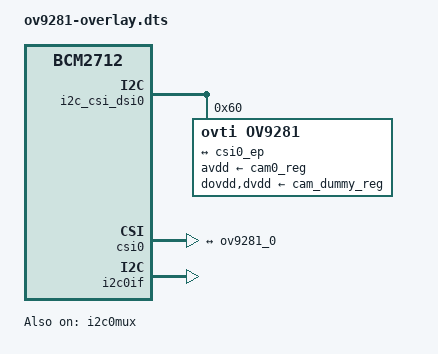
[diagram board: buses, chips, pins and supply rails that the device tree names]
/*
 * OV9281 Global Shutter Camera Device Tree Overlay
 * Raspberry Pi 5 - MIPI CSI-2 - 1MP Global Shutter
 */

/dts-v1/;
/plugin/;

/ {
    compatible = "brcm,bcm2712";
    
    fragment@0 {
        target = <&i2c_csi_dsi0>;
        __overlay__ {
            #address-cells = <1>;
            #size-cells = <0>;
            status = "okay";
            
            ov9281: ov9281@60 {
                compatible = "ovti,ov9281";
                reg = <0x60>;
                status = "okay";
                
                clocks = <&cam0_clk>;
                clock-names = "xvclk";
                
                avdd-supply = <&cam0_reg>;
                dovdd-supply = <&cam_dummy_reg>;
                dvdd-supply = <&cam_dummy_reg>;
                
                rotation = <0>;
                orientation = <2>;
                
                port {
                    ov9281_0: endpoint {
                        remote-endpoint = <&csi0_ep>;
                        clock-lanes = <0>;
                        data-lanes = <1 2>;
                        clock-noncontinuous;
                        link-frequencies = /bits/ 64 <400000000>;
                    };
                };
            };
        };
    };
    
    fragment@1 {
        target = <&csi0>;
        __overlay__ {
            status = "okay";
            
            port {
                csi0_ep: endpoint {
                    remote-endpoint = <&ov9281_0>;
                    data-lanes = <1 2>;
                };
            };
        };
    };
    
    fragment@2 {
        target = <&i2c0if>;
        __overlay__ {
            status = "okay";
        };
    };
    
    fragment@3 {
        target = <&i2c0mux>;
        __overlay__ {
            status = "okay";
        };
    };
    
    __overrides__ {
        rotation = <&ov9281>,"rotation:0";
        orientation = <&ov9281>,"orientation:0";
        media-controller = <&csi0>,"brcm,media-controller?";
        cam0 = <&ov9281>, "status";
    };
};
